# CC1312PSIP register map
File version: 1.0
CPU: CM4 1.0, other endian, MPU, FPU, 3 interrupt priority bits
Registers are 32-bit, read-write, reset 0x0 unless marked. A register's access mark holds for its fields unless they carry their own. Offsets are from the block's base; [hi:lo] are bit positions; {n}, {i} and the like mark numbered series.

## RFC_PWR — RF core power management This module contains clock control for all RF core sub-modules.
Base 0x40040000
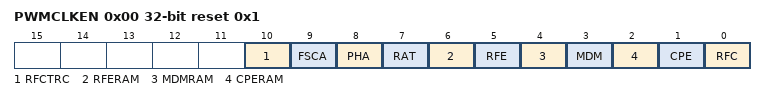
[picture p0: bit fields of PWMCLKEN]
0x00 PWMCLKEN reset 0x1 — RF Core Power Management and Clock Enable
  [10] RFCTRC — [10:10] Enable clock to the RF Core Tracer (RFCTRC) module.
  [9] FSCA — [9:9] Enable clock to the Frequency Synthesizer Calibration Accelerator (FSCA) module.
  [8] PHA — [8:8] Enable clock to the Packet Handling Accelerator (PHA) module.
  [7] RAT — [7:7] Enable clock to the Radio Timer (RAT) module.
  [6] RFERAM — [6:6] Enable clock to the RF Engine RAM module.
  [5] RFE — [5:5] Enable clock to the RF Engine (RFE) module.
  [4] MDMRAM — [4:4] Enable clock to the Modem RAM module.
  [3] MDM — [3:3] Enable clock to the Modem (MDM) module.
  [2] CPERAM — [2:2] Enable clock to the Command and Packet Engine (CPE) RAM module. As part of RF Core initialization, set this bit together with CPE bit to enable CPE to boot.
  [1] CPE — [1:1] Enable processor clock (hclk) to the Command and Packet Engine (CPE). As part of RF Core initialization, set this bit together with CPERAM bit to enable CPE to boot.
  [0] RFC ro — [0:0] Enable essential clocks for the RF Core interface. This includes the interconnect, the radio doorbell DBELL command interface, the power management (PWR) clock control module, and bus clock (sclk) for the CPE. To remove possibility of locking yourself out from the RF Core, this bit can not be cleared. If you need to disable all clocks to the RF Core, see the PRCM:RFCCLKG.CLK_EN register.

## RFC_RAT — RF core radio timer
Base 0x40043000
0x04 RATCNT — Radio Timer Counter Value
  [31:0] CNT — [31:0] Counter value. This is not writable while radio timer counter is enabled.
{0x80+4i} RATCH{i}VAL (i=0..7) — Timer Channel {i} Capture/Compare Register
  [31:0] VAL — [31:0] Capture/compare value. Only writable when the channel is configured for compare mode. In compare mode, a write to this register will auto-arm the channel.

## SMPH — MCU Semaphore Module This module provides 32 binary semaphores. The state of a binary semaphore is either taken or available. A semaphore does not implement any ownership attribute. Still, a semaphore can be used to handle mutual exclusion scenarios.
Base 0x40084000
{0x0+4i} SMPH{i} reset 0x1 (i=0..31) — MCU SEMAPHORE {i}
  [0] STAT — [0:0] Status when reading: 0: Semaphore is taken 1: Semaphore is available Reading the register causes it to change value to 0. Releasing the semaphore is done by writing 1.
{0x800+4i} PEEK{i} reset 0x1 (i=0..31) — MCU SEMAPHORE {i} ALIAS
  [0] STAT ro — [0:0] Status when reading: 0: Semaphore is taken 1: Semaphore is available Used for semaphore debugging. A read operation will not change register value. Register writing is not possible.

## SRAM_MMR — General Purpose RAM
Base 0x40035000
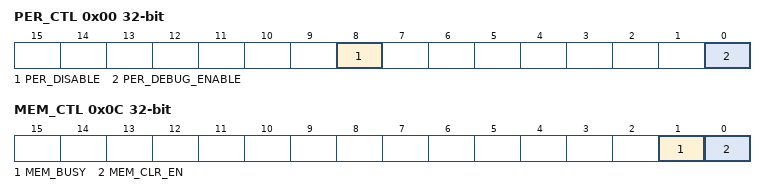
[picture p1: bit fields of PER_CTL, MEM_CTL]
0x00 PER_CTL — Parity Error Control Parity error check controls
  [8] PER_DISABLE — [8:8] Parity Status Disable 0: A parity error will update PER_CHK.PER_ADDR field 1: Parity error does not update PER_CHK.PER_ADDR field
  [0] PER_DEBUG_ENABLE — [0:0] Parity Error Debug Enable 0: Normal operation 1: An address offset can be written to PER_DBG.PER_DEBUG_ADDR and parity errors will be generated on reads from within this offset
0x04 PER_CHK — Parity Error Check Parity error check results
  [23:0] PER_ADDR ro — [23:0] Parity Error Address Offset Returns the last address offset which resulted in a parity error during an SRAM read. The address offset returned is always the word-aligned address that contains the location with the parity error. For parity faults on non word-aligned accesses, CPU_SCS:BFAR.ADDRESS will hold the address of the location that resulted in parity error.
0x08 PER_DBG — Parity Error Debug Parity error check debug address setting
  [23:0] PER_DEBUG_ADDR — [23:0] Debug Parity Error Address Offset When PER_CTL.PER_DEBUG is 1, this field is used to set a parity debug address offset. The address offset must be a word-aligned address. Writes within this address offset will force incorrect parity bits to be stored together with the data written. The following reads within this same address offset will thus result in parity errors to be generated.
0x0C MEM_CTL — Memory Control Controls memory initialization
  [1] MEM_BUSY ro — [1:1] Memory Busy status 0: Memory accepts transfers 1: Memory controller is busy during initialization. Read and write transfers are not performed.
  [0] MEM_CLR_EN — [0:0] Memory Contents Initialization enable Writing 1 to MEM_CLR_EN will start memory initialization. The contents of all byte locations will be initialized to 0x00. MEM_BUSY will be 1 until memory initialization has completed.
